# STM32G484xx register map
File version: 1.6
CPU: CM4 r0p1, little endian, MPU, FPU, 4 interrupt priority bits
Registers are 32-bit, read-write, reset 0x0 unless marked. A register's access mark holds for its fields unless they carry their own. Offsets are from the block's base; [hi:lo] are bit positions; {n}, {i} and the like mark numbered series; 'fields as' and 'values as' point back to an identical list.

## VREFBUF — Voltage reference buffer
Base 0x40010030
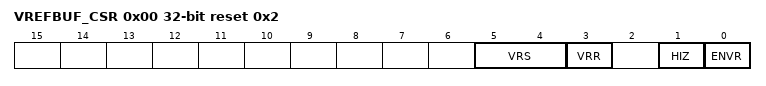
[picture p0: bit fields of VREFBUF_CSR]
0x00 VREFBUF_CSR access per field reset 0x2 — VREF_BUF Control and Status Register
  [5:4] VRS rw — Voltage reference scale
  [3] VRR ro — Voltage reference buffer ready
  [1] HIZ rw — High impedence mode for the VREF_BUF
  [0] ENVR rw — Enable Voltage Reference
0x04 VREFBUF_CCR — VREF_BUF Calibration Control Register
  [5:0] TRIM — Trimming code

## COMP — Comparator control and status register
Base 0x40010200
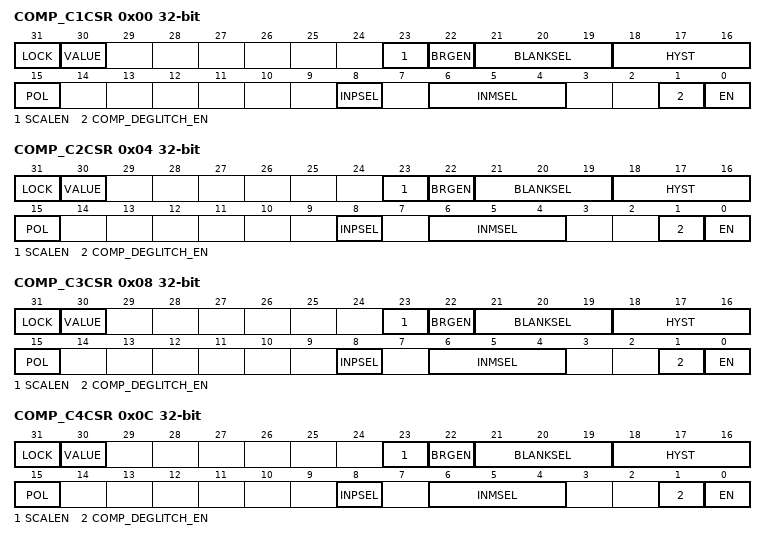
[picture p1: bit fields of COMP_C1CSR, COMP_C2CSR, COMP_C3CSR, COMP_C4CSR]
0x00 COMP_C1CSR access per field — Comparator control/status register
  [31] LOCK rw, [30] VALUE ro, [23] SCALEN rw, [22] BRGEN rw, [21:19] BLANKSEL rw, [18:16] HYST rw, [15] POL rw, [8] INPSEL rw, [6:4] INMSEL rw, [1] COMP_DEGLITCH_EN rw, [0] EN rw
0x04 COMP_C2CSR access per field — Comparator control/status register
  fields as COMP_C1CSR
0x08 COMP_C3CSR access per field — Comparator control/status register
  fields as COMP_C1CSR
0x0C COMP_C4CSR access per field — Comparator control/status register
  fields as COMP_C1CSR
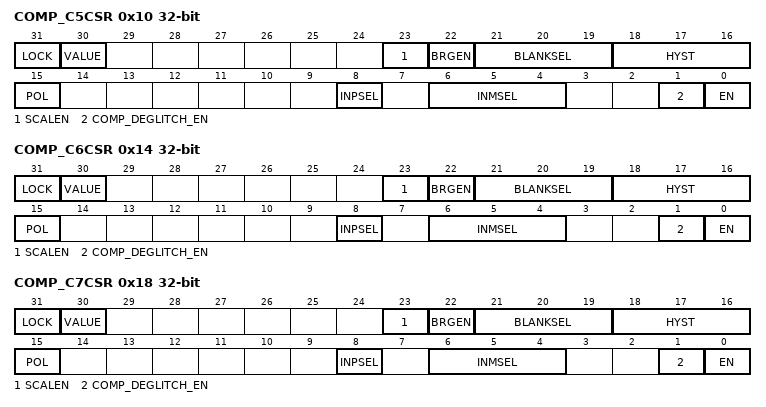
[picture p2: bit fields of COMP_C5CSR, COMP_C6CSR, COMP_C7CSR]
0x10 COMP_C5CSR access per field — Comparator control/status register
  fields as COMP_C1CSR
0x14 COMP_C6CSR access per field — Comparator control/status register
  fields as COMP_C1CSR
0x18 COMP_C7CSR access per field — Comparator control/status register
  fields as COMP_C1CSR

## OPAMP — Operational amplifiers
Base 0x40010300
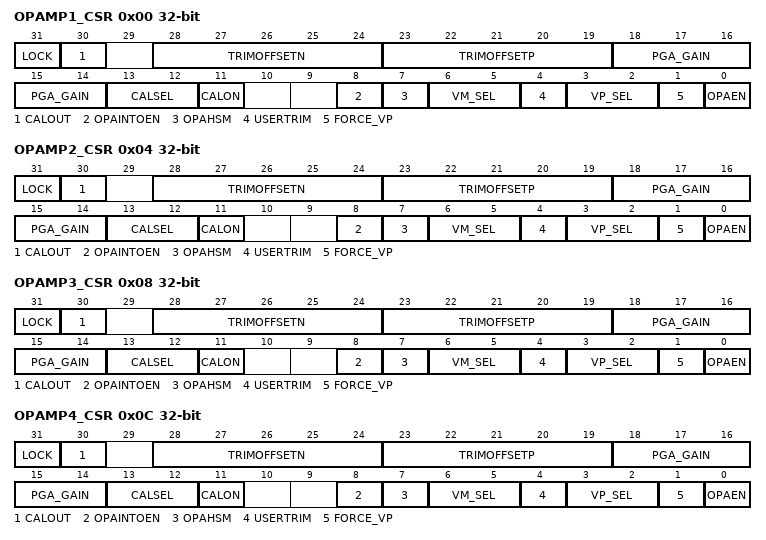
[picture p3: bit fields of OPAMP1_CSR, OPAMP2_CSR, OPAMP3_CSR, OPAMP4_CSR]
0x00 OPAMP1_CSR — OPAMP1 control/status register
  [31] LOCK
  [30] CALOUT
  [28:24] TRIMOFFSETN
  [23:19] TRIMOFFSETP
  [18:14] PGA_GAIN
  [13:12] CALSEL
  [11] CALON
  [8] OPAINTOEN
  [7] OPAHSM
  [6:5] VM_SEL
  [4] USERTRIM
  [3:2] VP_SEL
  [1] FORCE_VP
  [0] OPAEN — Operational amplifier Enable
0x04 OPAMP2_CSR — OPAMP2 control/status register
  fields as OPAMP1_CSR
0x08 OPAMP3_CSR — OPAMP3 control/status register
  fields as OPAMP1_CSR
0x0C OPAMP4_CSR — OPAMP4 control/status register
  fields as OPAMP1_CSR
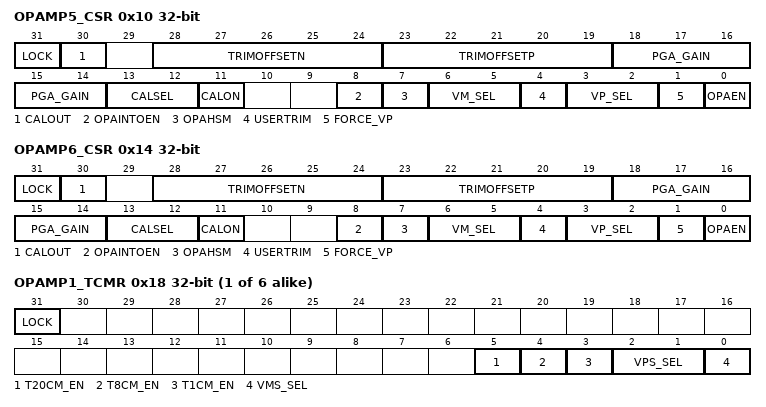
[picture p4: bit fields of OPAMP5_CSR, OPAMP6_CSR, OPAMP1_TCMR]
0x10 OPAMP5_CSR — OPAMP5 control/status register
  fields as OPAMP1_CSR
0x14 OPAMP6_CSR — OPAMP6 control/status register
  fields as OPAMP1_CSR
{0x14+4i} OPAMP{i}_TCMR (i=1..6) — OPAMP{i} control/status register
  [31] LOCK, [5] T20CM_EN, [4] T8CM_EN, [3] T1CM_EN, [2:1] VPS_SEL, [0] VMS_SEL

## HRTIM_Master — High Resolution Timer: Master Timers
Base 0x40016800
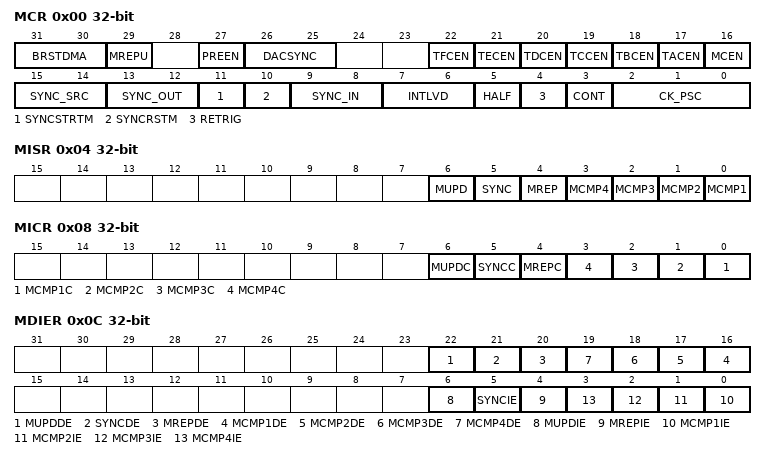
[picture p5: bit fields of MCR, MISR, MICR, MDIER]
0x00 MCR — Master Timer Control Register
  [31:30] BRSTDMA — Burst DMA Update
  [29] MREPU — Master Timer Repetition update
  [27] PREEN — Preload enable
  [26:25] DACSYNC — AC Synchronization
  [22] TFCEN — Timer F counter enable
  [21] TECEN — Timer E counter enable
  [20] TDCEN — Timer D counter enable
  [19] TCCEN — Timer C counter enable
  [18] TBCEN — Timer B counter enable
  [17] TACEN — Timer A counter enable
  [16] MCEN — Master Counter enable
  [15:14] SYNC_SRC — Synchronization source
  [13:12] SYNC_OUT — Synchronization output
  [11] SYNCSTRTM — Synchronization Starts Master
  [10] SYNCRSTM — Synchronization Resets Master
  [9:8] SYNC_IN — synchronization input
  [7:6] INTLVD — Interleaved mode
  [5] HALF — Half mode enable
  [4] RETRIG — Master Re-triggerable mode
  [3] CONT — Master Continuous mode
  [2:0] CK_PSC — HRTIM Master Clock prescaler
0x04 MISR ro — Master Timer Interrupt Status Register
  [6] MUPD — Master Update Interrupt Flag
  [5] SYNC — Sync Input Interrupt Flag
  [4] MREP — Master Repetition Interrupt Flag
  [n-1] MCMP{n} (n=1..4) — Master Compare {n} Interrupt Flag
0x08 MICR wo — Master Timer Interrupt Clear Register
  [6] MUPDC — Master update Interrupt flag clear
  [5] SYNCC — Sync Input Interrupt flag clear
  [4] MREPC — Repetition Interrupt flag clear
  [n-1] MCMP{n}C (n=1..4) — Master Compare {n} Interrupt flag clear
0x0C MDIER — HRTIM Master Timer DMA / Interrupt Enable Register
  [22] MUPDDE, [21] SYNCDE, [20] MREPDE, [n+15] MCMP{n}DE (n=1..4), [6] MUPDIE, [5] SYNCIE, [4] MREPIE, [n-1] MCMP{n}IE (n=1..4)
0x10 MCNTR — Master Timer Counter Register
  [15:0] MCNT — Counter value
0x14 MPER reset 0xFFFF — Master Timer Period Register
  [15:0] MPER — Master Timer Period value
0x18 MREP — Master Timer Repetition Register
  [7:0] MREP — Master Timer Repetition counter value
0x1C MCMP1R — Master Timer Compare 1 Register
  [15:0] MCMP1 — Master Timer Compare 1 value
{0x1C+4i} MCMP{i}R (i=2..4) — Master Timer Compare {i} Register
  [15:0] MCMP{i} — Master Timer Compare {i} value
